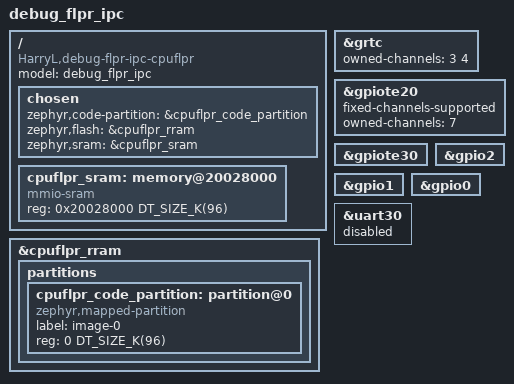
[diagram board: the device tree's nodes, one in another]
/dts-v1/;
#include <nordic/nrf54l15_cpuflpr.dtsi>
#include "debug_flpr_ipc_common.dtsi"

/delete-node/ &cpuflpr_sram;

/ {
	model = "debug_flpr_ipc";
	compatible = "HarryL,debug-flpr-ipc-cpuflpr";

	chosen {
		zephyr,code-partition = &cpuflpr_code_partition;
		zephyr,flash = &cpuflpr_rram;
		zephyr,sram = &cpuflpr_sram;
	};

	cpuflpr_sram: memory@20028000 {
		compatible = "mmio-sram";
		/* Size must be increased due to booting from SRAM */
		reg = <0x20028000 DT_SIZE_K(96)>;
		#address-cells = <1>;
		#size-cells = <1>;
		ranges = <0x0 0x20028000 0x18000>;
		status = "okay";
	};
};

&cpuflpr_rram {
	partitions {
		#address-cells = <1>;
		#size-cells = <1>;
		ranges;
		cpuflpr_code_partition: partition@0 {
			label = "image-0";
			compatible = "zephyr,mapped-partition";
			reg = <0 DT_SIZE_K(96)>;
		};
	};
};

&grtc {
	owned-channels = <3 4>;
	status = "okay";
};

&gpiote20 {
	fixed-channels-supported;
	owned-channels = <7>;
	status = "okay";
};

&gpiote30 {
	status = "okay";
};

&gpio2 {
	status = "okay";
};

&gpio1 {
	status = "okay";
};

&gpio0 {
	status = "okay";
};

&uart30 {
	status = "disabled";
};
